# STM32H757xx_CM4 register map
File version: 1.0
Registers are 32-bit, read-write, reset 0x0 unless marked. A register's access mark holds for its fields unless they carry their own. Offsets are from the block's base; [hi:lo] are bit positions; 'fields as' and 'values as' point back to an identical list.

## FMC_Bank2_R — Flexible Memory Controller Bank2
Base 0x52004060
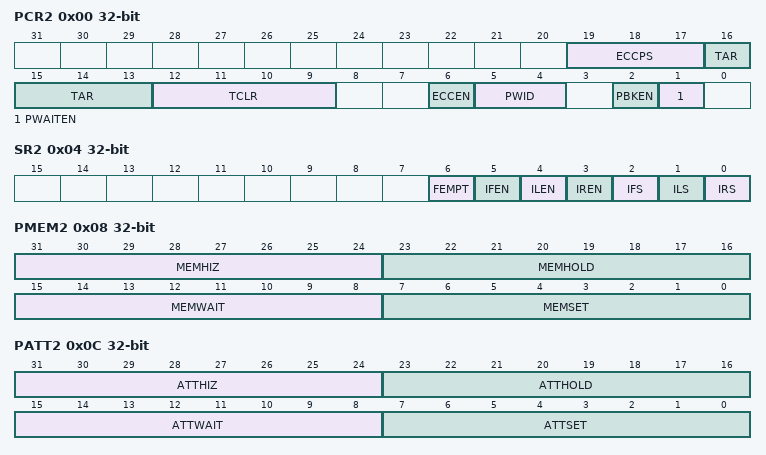
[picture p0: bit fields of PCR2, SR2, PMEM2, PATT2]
0x00 PCR2 — NAND Flash control register 2
  [19:17] ECCPS — ECCPS[1:0] bits (ECC page size)
  [16:13] TAR — TAR[3:0] bits (ALE to RE delay)
  [12:9] TCLR — TCLR[3:0] bits (CLE to RE delay)
  [6] ECCEN — ECC computation logic enable bit
  [5:4] PWID — PWID[1:0] bits (NAND Flash databus width)
  [2] PBKEN — NAND Flash memory bank enable bit
  [1] PWAITEN — Wait feature enable bit
0x04 SR2 — NAND Flash FIFO status and interrupt register 2
  [6] FEMPT — FIFO empty
  [5] IFEN — Interrupt Falling Edge detection Enable bit
  [4] ILEN — Interrupt Level detection Enable bit
  [3] IREN — Interrupt Rising Edge detection Enable bit
  [2] IFS — Interrupt Falling Edge status
  [1] ILS — Interrupt Level status
  [0] IRS — Interrupt Rising Edge status
0x08 PMEM2 — NAND Flash Common memory space timing register 2
  [31:24] MEMHIZ — MEMHIZ[7:0] bits (Common memory databus HiZ time)
  [23:16] MEMHOLD — MEMHOLD[7:0] bits (Common memory hold time)
  [15:8] MEMWAIT — MEMWAIT[7:0] bits (Common memory wait time)
  [7:0] MEMSET — MEMSET[7:0] bits (Common memory setup time)
0x0C PATT2 — NAND Flash Attribute memory space timing register 2
  [31:24] ATTHIZ — ATTHIZ[7:0] bits (Attribute memory databus HiZ time)
  [23:16] ATTHOLD — ATTHOLD[7:0] bits (Attribute memory hold time)
  [15:8] ATTWAIT — ATTWAIT[7:0] bits (Attribute memory wait time)
  [7:0] ATTSET — ATTSET[7:0] bits (Attribute memory setup time)
0x14 ECCR2 — NAND Flash ECC result registers 2

## FMC_Bank3_R — Flexible Memory Controller Bank3
Base 0x52004080
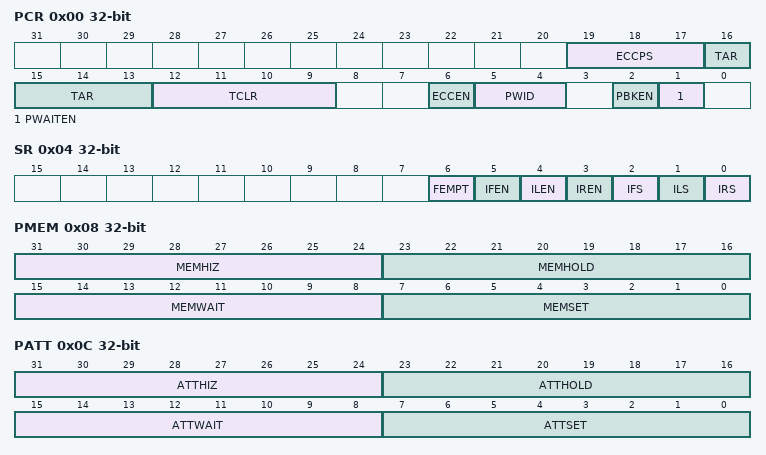
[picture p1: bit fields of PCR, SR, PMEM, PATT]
0x00 PCR — NAND Flash control register 3
  [19:17] ECCPS — ECCPS[1:0] bits (ECC page size)
  [16:13] TAR — TAR[3:0] bits (ALE to RE delay)
  [12:9] TCLR — TCLR[3:0] bits (CLE to RE delay)
  [6] ECCEN — ECC computation logic enable bit
  [5:4] PWID — PWID[1:0] bits (NAND Flash databus width)
  [2] PBKEN — NAND Flash memory bank enable bit
  [1] PWAITEN — Wait feature enable bit
0x04 SR — NAND Flash FIFO status and interrupt register 3
  [6] FEMPT — FIFO empty
  [5] IFEN — Interrupt Falling Edge detection Enable bit
  [4] ILEN — Interrupt Level detection Enable bit
  [3] IREN — Interrupt Rising Edge detection Enable bit
  [2] IFS — Interrupt Falling Edge status
  [1] ILS — Interrupt Level status
  [0] IRS — Interrupt Rising Edge status
0x08 PMEM — NAND Flash Common memory space timing register 3
  [31:24] MEMHIZ — MEMHIZ[7:0] bits (Common memory databus HiZ time)
  [23:16] MEMHOLD — MEMHOLD[7:0] bits (Common memory hold time)
  [15:8] MEMWAIT — MEMWAIT[7:0] bits (Common memory wait time)
  [7:0] MEMSET — MEMSET[7:0] bits (Common memory setup time)
0x0C PATT — NAND Flash Attribute memory space timing register 3
  [31:24] ATTHIZ — ATTHIZ[7:0] bits (Attribute memory databus HiZ time)
  [23:16] ATTHOLD — ATTHOLD[7:0] bits (Attribute memory hold time)
  [15:8] ATTWAIT — ATTWAIT[7:0] bits (Attribute memory wait time)
  [7:0] ATTSET — ATTSET[7:0] bits (Attribute memory setup time)
0x14 ECCR — NAND Flash ECC result registers 3

## FMC_Bank1E_R — Flexible Memory Controller Bank1E
Base 0x52004104
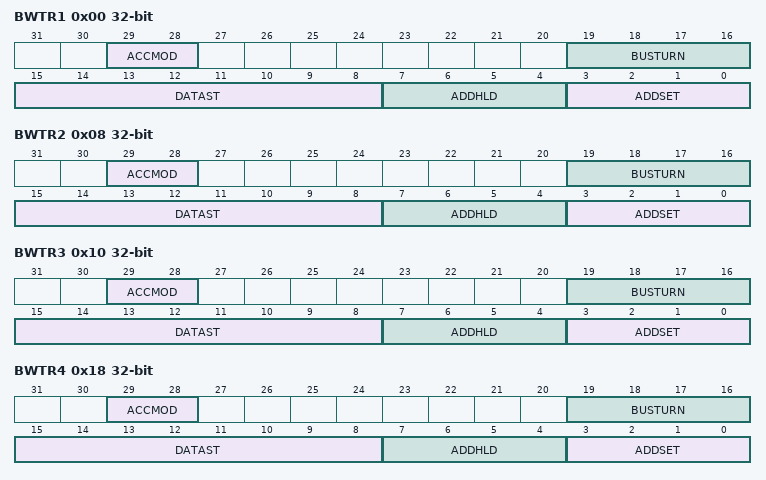
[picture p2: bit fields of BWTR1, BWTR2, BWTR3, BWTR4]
0x00 BWTR1 — NOR/PSRAM write timing registers
  [29:28] ACCMOD — ACCMOD[1:0] bits (Access mode)
  [19:16] BUSTURN — BUSTURN[3:0] bits (Bus turnaround phase duration)
  [15:8] DATAST — DATAST [3:0] bits (Data-phase duration)
  [7:4] ADDHLD — ADDHLD[3:0] bits (Address-hold phase duration)
  [3:0] ADDSET — ADDSET[3:0] bits (Address setup phase duration)
0x08 BWTR2 — NOR/PSRAM write timing registers
  fields as BWTR1
0x10 BWTR3 — NOR/PSRAM write timing registers
  fields as BWTR1
0x18 BWTR4 — NOR/PSRAM write timing registers
  fields as BWTR1

## FMC_Bank5_6_R — Flexible Memory Controller Bank5 and 6
Base 0x52004140
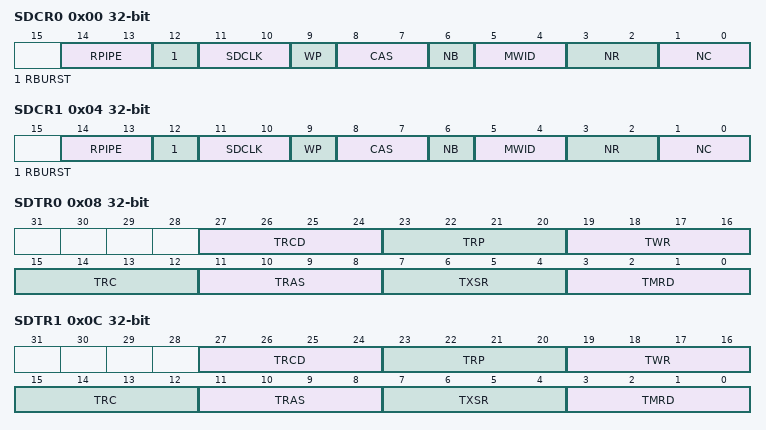
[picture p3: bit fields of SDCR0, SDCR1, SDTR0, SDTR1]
0x00 SDCR0 — SDRAM Control registers
  [14:13] RPIPE — Write protection
  [12] RBURST — Read burst
  [11:10] SDCLK — SDRAM clock configuration
  [9] WP — Write protection
  [8:7] CAS — CAS[1:0] bits (CAS latency)
  [6] NB — Number of internal bank
  [5:4] MWID — NR[1:0] bits (Number of row bits)
  [3:2] NR — NR[1:0] bits (Number of row bits)
  [1:0] NC — NC[1:0] bits (Number of column bits)
0x04 SDCR1 — SDRAM Control registers
  fields as SDCR0
0x08 SDTR0 — SDRAM Timing registers
  [27:24] TRCD — TRP[2:0] bits (Row to column delay)
  [23:20] TRP — TRP[2:0] bits (Row precharge delay)
  [19:16] TWR — TRC[2:0] bits (Write recovery delay)
  [15:12] TRC — TRC[2:0] bits (Row cycle delay)
  [11:8] TRAS — TRAS[3:0] bits (Self refresh time)
  [7:4] TXSR — TXSR[3:0] bits (Exit self refresh)
  [3:0] TMRD — TMRD[3:0] bits (Load mode register to active)
0x0C SDTR1 — SDRAM Timing registers
  fields as SDTR0
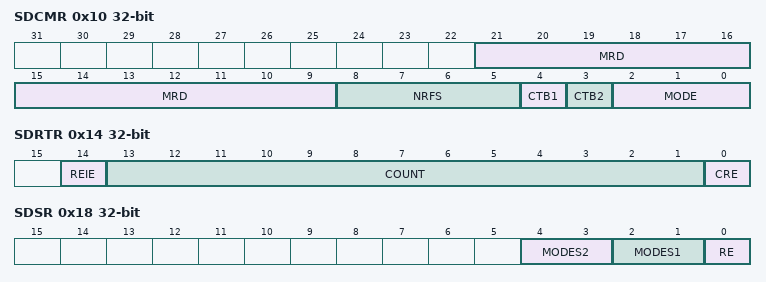
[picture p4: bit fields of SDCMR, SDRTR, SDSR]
0x10 SDCMR — SDRAM Command Mode register
  [21:9] MRD — MRD[12:0] bits (Mode register definition)
  [8:5] NRFS — NRFS[3:0] bits (Number of auto-refresh)
  [4] CTB1 — Command target 1
  [3] CTB2 — Command target 2
  [2:0] MODE — MODE[2:0] bits (Command mode)
0x14 SDRTR — SDRAM Refresh Timer register
  [14] REIE — RES interrupt enable
  [13:1] COUNT — COUNT[12:0] bits (Refresh timer count)
  [0] CRE — Clear refresh error flag
0x18 SDSR — SDRAM Status register
  [4:3] MODES2 — MODES2[1:0]bits (Status mode for bank 2)
  [2:1] MODES1 — MODES1[1:0]bits (Status mode for bank 1)
  [0] RE — Refresh error flag
